# nrf5340 register map
Vendor: Nordic Semiconductor; Series: nrf53; File version: 1
CPU: CM33 r0p2, little endian, MPU, FPU, 3 interrupt priority bits
Registers are 32-bit, read-write, reset 0x0 unless marked. A register's access mark holds for its fields unless they carry their own. Offsets are from the block's base; [hi:lo] are bit positions; lines under a group give offsets from that group; {n}, {i} and the like mark numbered series.

## UICR_S — User Information Configuration Registers User Information Configuration Registers
Base 0x00FF8000
0x00 APPROTECT reset 0xFFFFFFFF — Access port protection
  [31:0] PALL — Blocks debugger read/write access to all CPU registers and memory mapped addresses except for the Control Access Port registers.
    0xFFFFFFFF=Disabled; 0=Enabled
0x0C EXTSUPPLY reset 0xFFFFFFFF — Enable external circuitry to be supplied from VDD pin. Applicable in 'High voltage mode' only.
  [0] EXTSUPPLY — Enable external circuitry to be supplied from VDD pin (output of VREGH stage).
    1=Disabled (No current can be drawn from the VDD pin.); 0=Enabled (It is allowed to supply external circuitry from the VDD pin.)
0x10 VREGHVOUT reset 0xFFFFFFFF — GPIO reference voltage / external output supply voltage in 'High voltage mode'.
  [2:0] VREGHVOUT — VREGH regulator output voltage. The maximum output voltage from this stage is given as VDDH - VEXDIF.
    0=1V8 (1.8 V); 1=2V1 (2.1 V); 2=2V4 (2.4 V); 3=2V7 (2.7 V); 4=3V0 (3.0 V); 5=3V3 (3.3 V); 7=DEFAULT (Default voltage: 1.8 V)
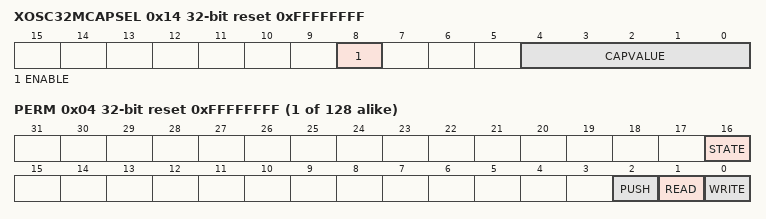
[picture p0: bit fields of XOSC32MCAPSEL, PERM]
0x14 XOSC32MCAPSEL reset 0xFFFFFFFF — Capacitor selection and enable on XC1 and XC2
  [8] ENABLE — Enable on-chip capacitors on XC1 and XC2, value given by CAPVAL
    1=Disabled (Capacitor disabled (use external caps)); 0=Enabled (Capacitor enabled)
  [4:0] CAPVALUE — Capacitance value for built-in load caps on XC1 and XC2
    0=C070 (Set cap to 7.0 pF); 1=C075 (Set cap to 7.5 pF); 2=C080 (Set cap to 8.0 pF); 3=C085 (Set cap to 8.5 pF); 4=C090 (Set cap to 9.0 pF); 5=C095 (Set cap to 9.5 pF); 6=C100 (Set cap to 10.0 pF); 7=C105 (Set cap to 10.5 pF); 8=C110 (Set cap to 11.0 pF); 9=C115 (Set cap to 11.5 pF); 10=C120 (Set cap to 12.0 pF); 11=C125 (Set cap to 12.5 pF); 12=C130 (Set cap to 13.0 pF); 13=C135 (Set cap to 13.5 pF); 14=C140 (Set cap to 14.0 pF); 15=C145 (Set cap to 14.5 pF); 16=C150 (Set cap to 15.0 pF); 17=C155 (Set cap to 15.5 pF); 18=C160 (Set cap to 16.0 pF); 19=C165 (Set cap to 16.5 pF); 20=C170 (Set cap to 17.0 pF); 21=C175 (Set cap to 17.5 pF); 22=C180 (Set cap to 18.0 pF); 23=C185 (Set cap to 18.5 pF); 24=C190 (Set cap to 19.0 pF); 25=C195 (Set cap to 19.5 pF); 26=C200 (Set cap to 20.0 pF)
0x18 TBD reset 0xFFFFFFFF — TDB
0x1C SECUREAPPROTECT reset 0xFFFFFFFF — Secure Access port protection
  [31:0] PALL — Blocks debugger read/write access to all secure CPU registers and secure memory mapped addresses
    0xFFFFFFFF=Disabled; 0=Enabled
0x20 ERASEPROTECT reset 0xFFFFFFFF — Erase protection
  [31:0] PALL — Blocks NVMC ERASEALL and CTRLAP ERASEALL functionality
    0xFFFFFFFF=Disabled; 0=Enabled
0x24 TINSTANCE reset 0xFFFFFFFF — SW-DP Target instance
  [31:28] TINSTANCE — TINSTANCE bits are negated and used in the SW-DP DLPIDR.TINSTANCE field. E.g. 0xF in this field is translated to 0x0 in DLPIDR.TINSTANCE field.
{0x100+4i} OTP[{i}] (i=0..191) reset 0xFFFFFFFF — Description collection: OTP bits [31+n*32:0+n*32].
  [31:0] OTP — Bits [31+n*32:0+n*32] of OTP Region
0x400 KEYSLOT group — Unspecified
  {0x0+8j} CONFIG[{j}] (j=0..127) group — Unspecified
    0x00 DEST reset 0xFFFFFFFF — Description cluster: Destination address where content of registers KEYSLOT.KEYn.VALUE[0-3] will be pushed by KMU. Note that this address MUST match that of a peripherals APB mapped write-only key registers, else the KMU can push this key value into an address range which the CPU can potentially read!
      [31:0] DEST — Destination address for key slot n
    0x04 PERM reset 0xFFFFFFFF — Description cluster: Define permissions for key slot n. Bits 0-15 and 16-31 can only be written once.
      [16] STATE — Revocation state for key slot n
        0=Revoked (Registers KEYSLOTn.KEY.VALUE[0-3] can no longer be read or pushed); 1=Active (Registers KEYSLOTn.KEY.VALUE[0-3] are readable (if enabled) and can be pushed (if enabled))
      [2] PUSH — Push permission for key slot n
        0=Disabled (Content of registers KEYSLOT.KEYn.VALUE[0-3] can not be pushed, but can be read if field READ is 'Enabled'); 1=Enabled (Content of registers KEYSLOT.KEYn.VALUE[0-3] can be pushed over secure APB. Register KEYSLOT.CONFIGn.DEST must contain a valid destination address!)
      [1] READ — Read permission for key slot n.
        0=Disabled (Disable read from registers KEYSLOT.KEYn.VALUE[0-3]); 1=Enabled (Registers KEYSLOT.KEYn.VALUE[0-3] can be read)
      [0] WRITE — Write permission for key slot n
        0=Disabled (Disable write to registers KEYSLOT.KEYn.VALUE[0-3]); 1=Enabled (Registers KEYSLOT.KEYn.VALUE[0-3] can be written)
  {0x400+0x10*j} KEY[{j}] (j=0..127) group — Unspecified
    {0x0+4k} VALUE[{k}] (k=0..3) reset 0xFFFFFFFF — Description collection: Define bits [31+o*32:0+o*32] of value assigned to key slot n
      [31:0] VALUE — Define bits [31+o*32:0+o*32] of value assigned to key slot n
